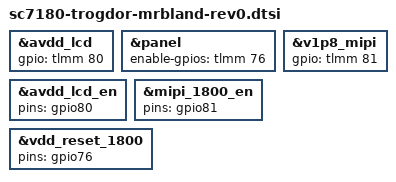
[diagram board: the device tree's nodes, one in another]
// SPDX-License-Identifier: (GPL-2.0+ OR MIT)
/*
 * Google Mrbland board device tree source
 *
 * Copyright 2021 Google LLC.
 *
 */

/dts-v1/;

#include "sc7180-trogdor-mrbland.dtsi"

&avdd_lcd {
	gpio = <&tlmm 80 GPIO_ACTIVE_HIGH>;
};

&panel {
	enable-gpios = <&tlmm 76 GPIO_ACTIVE_HIGH>;
};

&v1p8_mipi {
	gpio = <&tlmm 81 GPIO_ACTIVE_HIGH>;
};

/* PINCTRL - modifications to sc7180-trogdor-mrbland.dtsi */
&avdd_lcd_en {
	pins = "gpio80";
};

&mipi_1800_en {
	pins = "gpio81";
};

&vdd_reset_1800 {
	pins = "gpio76";
};
